AUTOSAR XML (schema 00047)
package /BswM/ServiceSwComponentTypes
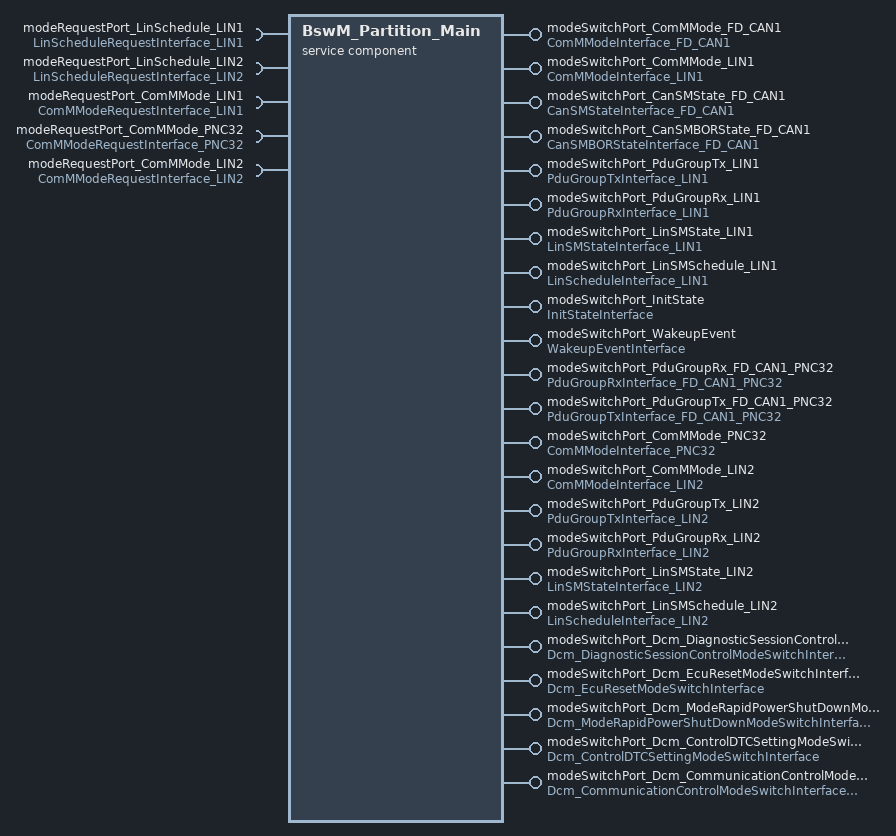
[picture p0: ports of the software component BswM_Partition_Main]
  service sw component type BswM_Partition_Main
    18 x provide port:
      modeSwitchPort_ComMMode_FD_CAN1: mode-switch-sender-com-spec{enhanced-mode-api=false, mode-group=ComMMode_FD_CAN1, queue-length=1}, provided-interface=ComMModeInterface_FD_CAN1
      modeSwitchPort_ComMMode_LIN1: mode-switch-sender-com-spec{enhanced-mode-api=false, mode-group=ComMMode_LIN1, queue-length=1}, provided-interface=ComMModeInterface_LIN1
      modeSwitchPort_CanSMState_FD_CAN1: mode-switch-sender-com-spec{enhanced-mode-api=false, mode-group=CanSMState_FD_CAN1, queue-length=1}, provided-interface=CanSMStateInterface_FD_CAN1
      modeSwitchPort_CanSMBORState_FD_CAN1: mode-switch-sender-com-spec{enhanced-mode-api=false, mode-group=CanSMBORState_FD_CAN1, queue-length=1}, provided-interface=CanSMBORStateInterface_FD_CAN1
      modeSwitchPort_PduGroupTx_LIN1: mode-switch-sender-com-spec{enhanced-mode-api=false, mode-group=PduGroupTx_LIN1, queue-length=1}, provided-interface=PduGroupTxInterface_LIN1
      modeSwitchPort_PduGroupRx_LIN1: mode-switch-sender-com-spec{enhanced-mode-api=false, mode-group=PduGroupRx_LIN1, queue-length=1}, provided-interface=PduGroupRxInterface_LIN1
      modeSwitchPort_LinSMState_LIN1: mode-switch-sender-com-spec{enhanced-mode-api=false, mode-group=LinSMState_LIN1, queue-length=1}, provided-interface=LinSMStateInterface_LIN1
      modeSwitchPort_LinSMSchedule_LIN1: mode-switch-sender-com-spec{enhanced-mode-api=false, mode-group=LinSchedule_LIN1, queue-length=1}, provided-interface=LinScheduleInterface_LIN1
      modeSwitchPort_InitState: mode-switch-sender-com-spec{enhanced-mode-api=false, mode-group=InitState, queue-length=1}, provided-interface=InitStateInterface
      modeSwitchPort_WakeupEvent: mode-switch-sender-com-spec{enhanced-mode-api=false, mode-group=WakeupEvent, queue-length=1}, provided-interface=WakeupEventInterface
      modeSwitchPort_PduGroupRx_FD_CAN1_PNC32: mode-switch-sender-com-spec{enhanced-mode-api=false, mode-group=PduGroupRx_FD_CAN1_PNC32, queue-length=1}, provided-interface=PduGroupRxInterface_FD_CAN1_PNC32
      modeSwitchPort_PduGroupTx_FD_CAN1_PNC32: mode-switch-sender-com-spec{enhanced-mode-api=false, mode-group=PduGroupTx_FD_CAN1_PNC32, queue-length=1}, provided-interface=PduGroupTxInterface_FD_CAN1_PNC32
      modeSwitchPort_ComMMode_PNC32: mode-switch-sender-com-spec{enhanced-mode-api=false, mode-group=ComMMode_PNC32, queue-length=1}, provided-interface=ComMModeInterface_PNC32
      modeSwitchPort_ComMMode_LIN2: mode-switch-sender-com-spec{enhanced-mode-api=false, mode-group=ComMMode_LIN2, queue-length=1}, provided-interface=ComMModeInterface_LIN2
      modeSwitchPort_PduGroupTx_LIN2: mode-switch-sender-com-spec{enhanced-mode-api=false, mode-group=PduGroupTx_LIN2, queue-length=1}, provided-interface=PduGroupTxInterface_LIN2
      modeSwitchPort_PduGroupRx_LIN2: mode-switch-sender-com-spec{enhanced-mode-api=false, mode-group=PduGroupRx_LIN2, queue-length=1}, provided-interface=PduGroupRxInterface_LIN2
      modeSwitchPort_LinSMState_LIN2: mode-switch-sender-com-spec{enhanced-mode-api=false, mode-group=LinSMState_LIN2, queue-length=1}, provided-interface=LinSMStateInterface_LIN2
      modeSwitchPort_LinSMSchedule_LIN2: mode-switch-sender-com-spec{enhanced-mode-api=false, mode-group=LinSchedule_LIN2, queue-length=1}, provided-interface=LinScheduleInterface_LIN2
    5 x require port:
      modeRequestPort_LinSchedule_LIN1: nonqueued-receiver-com-spec=LinSchedule_LIN1, required-interface=LinScheduleRequestInterface_LIN1
      modeRequestPort_LinSchedule_LIN2: nonqueued-receiver-com-spec=LinSchedule_LIN2, required-interface=LinScheduleRequestInterface_LIN2
      modeRequestPort_ComMMode_LIN1: nonqueued-receiver-com-spec=ComMMode_LIN1, required-interface=ComMModeRequestInterface_LIN1
      modeRequestPort_ComMMode_PNC32: nonqueued-receiver-com-spec=ComMMode_PNC32, required-interface=ComMModeRequestInterface_PNC32
      modeRequestPort_ComMMode_LIN2: nonqueued-receiver-com-spec=ComMMode_LIN2, required-interface=ComMModeRequestInterface_LIN2
    5 x provide port:
      modeSwitchPort_Dcm_DiagnosticSessionControlModeSwitchInterface: mode-switch-sender-com-spec{enhanced-mode-api=false, mode-group=Dcm_DiagnosticSessionControlModeSwitchInterface, queue-length=1}, provided-interface=Dcm_DiagnosticSessionControlModeSwitchInterface
      modeSwitchPort_Dcm_EcuResetModeSwitchInterface: mode-switch-sender-com-spec{enhanced-mode-api=false, mode-group=Dcm_EcuResetModeSwitchInterface, queue-length=1}, provided-interface=Dcm_EcuResetModeSwitchInterface
      modeSwitchPort_Dcm_ModeRapidPowerShutDownModeSwitchInterface: mode-switch-sender-com-spec{enhanced-mode-api=false, mode-group=Dcm_ModeRapidPowerShutDownModeSwitchInterface, queue-length=1}, provided-interface=Dcm_ModeRapidPowerShutDownModeSwitchInterface
      modeSwitchPort_Dcm_ControlDTCSettingModeSwitchInterface: mode-switch-sender-com-spec{enhanced-mode-api=false, mode-group=Dcm_ControlDTCSettingModeSwitchInterface, queue-length=1}, provided-interface=Dcm_ControlDTCSettingModeSwitchInterface
      modeSwitchPort_Dcm_CommunicationControlModeSwitchInterface_ComMChannel_FD_CAN1: mode-switch-sender-com-spec{enhanced-mode-api=false, mode-group=Dcm_CommunicationControlModeSwitchInterface_ComMChannel_FD_CAN1, queue-length=1}, provided-interface=Dcm_CommunicationControlModeSwitchInterface_ComMChannel_FD_CAN1
    behavior SwcIB_BswM: data-type-mapping=[MAP_ComMMode, MAP_CanSMBORState, MAP_InitState, MAP_PduGroup, MAP_WakeupEvent, MAP_CanSMState, DcmDiagnosticSessionControl, DcmEcuReset, MAP_LinSchedule_LIN1, MAP_LinSMState, EcuModeMap, DcmCommunicationControl, DcmModeRapidPowerShutDown, DcmControlDTCSetting, DcmApplicationUpdated, DcmResponseOnEvent, DcmSecurityAccess, MAP_EthSMState, MAP_ComMMode_PNC, MAP_LinSchedule_LIN2], handle-termination-and-restart=NO-SUPPORT
      5 x data received event:
        DRE_BswM_Immediate_SwcModeRequest_ComMMode_LIN1_modeRequestPort_ComMMode_LIN1_ComMMode_LIN1: start-on-event=BswM_Immediate_SwcModeRequest_ComMMode_LIN1, data=modeRequestPort_ComMMode_LIN1.ComMMode_LIN1
        DRE_BswM_Immediate_SwcModeRequest_LinSchedule_LIN1_modeRequestPort_LinSchedule_LIN1_LinSchedule_LIN1: start-on-event=BswM_Immediate_SwcModeRequest_LinSchedule_LIN1, data=modeRequestPort_LinSchedule_LIN1.LinSchedule_LIN1
        DRE_BswM_Immediate_SwcModeRequest_LinSchedule_LIN2_modeRequestPort_LinSchedule_LIN2_LinSchedule_LIN2: start-on-event=BswM_Immediate_SwcModeRequest_LinSchedule_LIN2, data=modeRequestPort_LinSchedule_LIN2.LinSchedule_LIN2
        DRE_BswM_Immediate_SwcModeRequest_ComMMode_PNC32_modeRequestPort_ComMMode_PNC32_ComMMode_PNC32: start-on-event=BswM_Immediate_SwcModeRequest_ComMMode_PNC32, data=modeRequestPort_ComMMode_PNC32.ComMMode_PNC32
        DRE_BswM_Immediate_SwcModeRequest_ComMMode_LIN2_modeRequestPort_ComMMode_LIN2_ComMMode_LIN2: start-on-event=BswM_Immediate_SwcModeRequest_ComMMode_LIN2, data=modeRequestPort_ComMMode_LIN2.ComMMode_LIN2
      29 x runnable:
        BswM_Immediate_SwcModeRequest_ComMMode_LIN1: symbol=BswM_Immediate_ComMMode_LIN1
          data-receive-point-by-arguments:
            access DRPBA_BswM_Immediate_ComMMode_LIN1: accessed-variable=modeRequestPort_ComMMode_LIN1.ComMMode_LIN1
        BswM_Immediate_SwcModeRequest_LinSchedule_LIN1: symbol=BswM_Immediate_LinSchedule_LIN1
          data-receive-point-by-arguments:
            access DRPBA_BswM_Immediate_LinSchedule_LIN1: accessed-variable=modeRequestPort_LinSchedule_LIN1.LinSchedule_LIN1
        BswM_ActionList_RteSwitch_ComMMode_FD_CAN1: can-be-invoked-concurrently=true
          mode switch point MSP_BswM_ActionList_RteSwitch_ComMMode_FD_CAN1_modeSwitchPort_ComMMode_FD_CAN1_ComMMode_FD_CAN1: mode-group=modeSwitchPort_ComMMode_FD_CAN1.ComMMode_FD_CAN1
        BswM_ActionList_RteSwitch_ComMMode_LIN1: can-be-invoked-concurrently=true
          mode switch point MSP_BswM_ActionList_RteSwitch_ComMMode_LIN1_modeSwitchPort_ComMMode_LIN1_ComMMode_LIN1: mode-group=modeSwitchPort_ComMMode_LIN1.ComMMode_LIN1
        BswM_ActionList_RteSwitch_CanSMState_FD_CAN1: can-be-invoked-concurrently=true
          mode switch point MSP_BswM_ActionList_RteSwitch_CanSMState_FD_CAN1_modeSwitchPort_CanSMState_FD_CAN1_CanSMState_FD_CAN1: mode-group=modeSwitchPort_CanSMState_FD_CAN1.CanSMState_FD_CAN1
        BswM_ActionList_RteSwitch_CanSMBORState_FD_CAN1: can-be-invoked-concurrently=true
          mode switch point MSP_BswM_ActionList_RteSwitch_CanSMBORState_FD_CAN1_modeSwitchPort_CanSMBORState_FD_CAN1_CanSMBORState_FD_CAN1: mode-group=modeSwitchPort_CanSMBORState_FD_CAN1.CanSMBORState_FD_CAN1
        BswM_ActionList_RteSwitch_PduGroupTx_LIN1: can-be-invoked-concurrently=true
          mode switch point MSP_BswM_ActionList_RteSwitch_PduGroupTx_LIN1_modeSwitchPort_PduGroupTx_LIN1_PduGroupTx_LIN1: mode-group=modeSwitchPort_PduGroupTx_LIN1.PduGroupTx_LIN1
        BswM_ActionList_RteSwitch_PduGroupRx_LIN1: can-be-invoked-concurrently=true
          mode switch point MSP_BswM_ActionList_RteSwitch_PduGroupRx_LIN1_modeSwitchPort_PduGroupRx_LIN1_PduGroupRx_LIN1: mode-group=modeSwitchPort_PduGroupRx_LIN1.PduGroupRx_LIN1
        BswM_ActionList_RteSwitch_LinSMState_LIN1: can-be-invoked-concurrently=true
          mode switch point MSP_BswM_ActionList_RteSwitch_LinSMState_LIN1_modeSwitchPort_LinSMState_LIN1_LinSMState_LIN1: mode-group=modeSwitchPort_LinSMState_LIN1.LinSMState_LIN1
        BswM_ActionList_RteSwitch_LinSMSchedule_LIN1: can-be-invoked-concurrently=true
          mode switch point MSP_BswM_ActionList_RteSwitch_LinSMSchedule_LIN1_modeSwitchPort_LinSMSchedule_LIN1_LinSMSchedule_LIN1: mode-group=modeSwitchPort_LinSMSchedule_LIN1.LinSchedule_LIN1
        BswM_ActionList_RteSwitch_InitState: can-be-invoked-concurrently=true
          mode switch point MSP_BswM_ActionList_RteSwitch_InitState_modeSwitchPort_InitState_InitState: mode-group=modeSwitchPort_InitState.InitState
        BswM_ActionList_RteSwitch_WakeupEvent: can-be-invoked-concurrently=true
          mode switch point MSP_BswM_ActionList_RteSwitch_WakeupEvent_modeSwitchPort_WakeupEvent_WakeupEvent: mode-group=modeSwitchPort_WakeupEvent.WakeupEvent
        BswM_ActionList_RteSwitch_PduGroupRx_FD_CAN1_PNC32: can-be-invoked-concurrently=true
          mode switch point MSP_BswM_ActionList_RteSwitch_PduGroupRx_FD_CAN1_PNC32_modeSwitchPort_PduGroupRx_FD_CAN1_PNC32_PduGroupRx_FD_CAN1_PNC32: mode-group=modeSwitchPort_PduGroupRx_FD_CAN1_PNC32.PduGroupRx_FD_CAN1_PNC32
        BswM_ActionList_RteSwitch_PduGroupTx_FD_CAN1_PNC32: can-be-invoked-concurrently=true
          mode switch point MSP_BswM_ActionList_RteSwitch_PduGroupTx_FD_CAN1_PNC32_modeSwitchPort_PduGroupTx_FD_CAN1_PNC32_PduGroupTx_FD_CAN1_PNC32: mode-group=modeSwitchPort_PduGroupTx_FD_CAN1_PNC32.PduGroupTx_FD_CAN1_PNC32
        BswM_ActionList_RteSwitch_ComMMode_PNC32: can-be-invoked-concurrently=true
          mode switch point MSP_BswM_ActionList_RteSwitch_ComMMode_PNC32_modeSwitchPort_ComMMode_PNC32_ComMMode_PNC32: mode-group=modeSwitchPort_ComMMode_PNC32.ComMMode_PNC32
        BswM_Immediate_SwcModeRequest_ComMMode_PNC32: symbol=BswM_Immediate_ComMMode_PNC32
          data-receive-point-by-arguments:
            access DRPBA_BswM_Immediate_ComMMode_PNC32: accessed-variable=modeRequestPort_ComMMode_PNC32.ComMMode_PNC32
        BswM_Immediate_SwcModeRequest_LinSchedule_LIN2: symbol=BswM_Immediate_LinSchedule_LIN2
          data-receive-point-by-arguments:
            access DRPBA_BswM_Immediate_LinSchedule_LIN2: accessed-variable=modeRequestPort_LinSchedule_LIN2.LinSchedule_LIN2
        BswM_ActionList_RteSwitch_Dcm_ControlDTCSettingModeSwitchInterface: can-be-invoked-concurrently=true
          mode switch point MSP_BswM_ActionList_RteSwitch_Dcm_ControlDTCSettingModeSwitchInterface_modeSwitchPort_Dcm_ControlDTCSettingModeSwitchInterface_Dcm_ControlDTCSettingModeSwitchInterface: mode-group=modeSwitchPort_Dcm_ControlDTCSettingModeSwitchInterface.Dcm_ControlDTCSettingModeSwitchInterface
        BswM_ActionList_RteSwitch_DcmDiagnosticSessionControl: can-be-invoked-concurrently=true
          mode switch point MSP_BswM_ActionList_RteSwitch_DcmDiagnosticSessionControl_modeSwitchPort_Dcm_DiagnosticSessionControlModeSwitchInterface_Dcm_DiagnosticSessionControlModeSwitchInterface: mode-group=modeSwitchPort_Dcm_DiagnosticSessionControlModeSwitchInterface.Dcm_DiagnosticSessionControlModeSwitchInterface
        BswM_ActionList_RteSwitch_Dcm_EcuResetModeSwitchInterface: can-be-invoked-concurrently=true
          mode switch point MSP_BswM_ActionList_RteSwitch_Dcm_EcuResetModeSwitchInterface_modeSwitchPort_Dcm_EcuResetModeSwitchInterface_Dcm_EcuResetModeSwitchInterface: mode-group=modeSwitchPort_Dcm_EcuResetModeSwitchInterface.Dcm_EcuResetModeSwitchInterface
        BswM_ActionList_RteSwitch_Dcm_CommunicationControlModeSwitchInterface_ComMChannel_FD_CAN1: can-be-invoked-concurrently=true
          mode switch point MSP_BswM_ActionList_RteSwitch_Dcm_CommunicationControlModeSwitchInterface_ComMChannel_FD_CAN1_modeSwitchPort_Dcm_CommunicationControlModeSwitchInterface_ComMChannel_FD_CAN1_Dcm_CommunicationControlModeSwitchInterface_ComMChannel_FD_CAN1: mode-group=modeSwitchPort_Dcm_CommunicationControlModeSwitchInterface_ComMChannel_FD_CAN1.Dcm_CommunicationControlModeSwitchInterface_ComMChannel_FD_CAN1
        BswM_ActionList_RteSwitch_Dcm_DiagnosticSessionControlModeSwitchInterface: can-be-invoked-concurrently=true
          mode switch point MSP_BswM_ActionList_RteSwitch_Dcm_DiagnosticSessionControlModeSwitchInterface_modeSwitchPort_Dcm_DiagnosticSessionControlModeSwitchInterface_Dcm_DiagnosticSessionControlModeSwitchInterface: mode-group=modeSwitchPort_Dcm_DiagnosticSessionControlModeSwitchInterface.Dcm_DiagnosticSessionControlModeSwitchInterface
        BswM_ActionList_RteSwitch_Dcm_ModeRapidPowerShutDownModeSwitchInterface: can-be-invoked-concurrently=true
          mode switch point MSP_BswM_ActionList_RteSwitch_Dcm_ModeRapidPowerShutDownModeSwitchInterface_modeSwitchPort_Dcm_ModeRapidPowerShutDownModeSwitchInterface_Dcm_ModeRapidPowerShutDownModeSwitchInterface: mode-group=modeSwitchPort_Dcm_ModeRapidPowerShutDownModeSwitchInterface.Dcm_ModeRapidPowerShutDownModeSwitchInterface
        BswM_ActionList_RteSwitch_ComMMode_LIN2: can-be-invoked-concurrently=true
          mode switch point MSP_BswM_ActionList_RteSwitch_ComMMode_LIN2_modeSwitchPort_ComMMode_LIN2_ComMMode_LIN2: mode-group=modeSwitchPort_ComMMode_LIN2.ComMMode_LIN2
        BswM_ActionList_RteSwitch_PduGroupTx_LIN2: can-be-invoked-concurrently=true
          mode switch point MSP_BswM_ActionList_RteSwitch_PduGroupTx_LIN2_modeSwitchPort_PduGroupTx_LIN2_PduGroupTx_LIN2: mode-group=modeSwitchPort_PduGroupTx_LIN2.PduGroupTx_LIN2
        BswM_ActionList_RteSwitch_PduGroupRx_LIN2: can-be-invoked-concurrently=true
          mode switch point MSP_BswM_ActionList_RteSwitch_PduGroupRx_LIN2_modeSwitchPort_PduGroupRx_LIN2_PduGroupRx_LIN2: mode-group=modeSwitchPort_PduGroupRx_LIN2.PduGroupRx_LIN2
        BswM_ActionList_RteSwitch_LinSMState_LIN2: can-be-invoked-concurrently=true
          mode switch point MSP_BswM_ActionList_RteSwitch_LinSMState_LIN2_modeSwitchPort_LinSMState_LIN2_LinSMState_LIN2: mode-group=modeSwitchPort_LinSMState_LIN2.LinSMState_LIN2
        BswM_ActionList_RteSwitch_LinSMSchedule_LIN2: can-be-invoked-concurrently=true
          mode switch point MSP_BswM_ActionList_RteSwitch_LinSMSchedule_LIN2_modeSwitchPort_LinSMSchedule_LIN2_LinSchedule_LIN2: mode-group=modeSwitchPort_LinSMSchedule_LIN2.LinSchedule_LIN2
        BswM_Immediate_SwcModeRequest_ComMMode_LIN2: symbol=BswM_Immediate_ComMMode_LIN2
          data-receive-point-by-arguments:
            access DRPBA_BswM_Immediate_ComMMode_LIN2: accessed-variable=modeRequestPort_ComMMode_LIN2.ComMMode_LIN2
  swc implementation SwcImplementation_BswM: programming-language=C, swc-bsw-mapping=SwcBswMapping_BswM, behavior=SwcIB_BswM
package /BswM/SwcBswMappings
  swc bsw mapping SwcBswMapping_BswM: bsw-behavior=BswIB_BswM, swc-behavior=SwcIB_BswM
